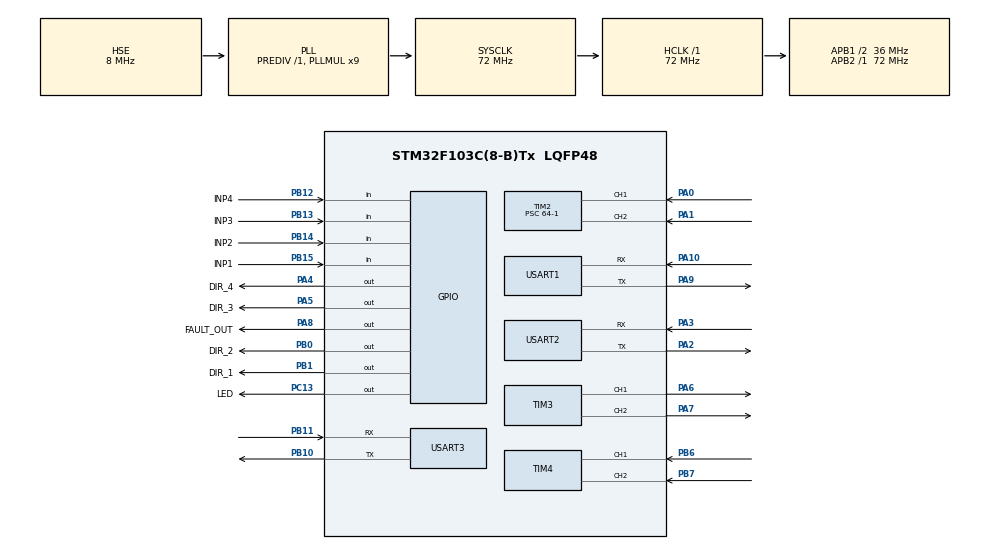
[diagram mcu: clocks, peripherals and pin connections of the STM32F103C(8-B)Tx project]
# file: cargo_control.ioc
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FREERTOS.Mutexes01=modbusMutex,Dynamic,NULL,Available
FREERTOS.Queues01=modbusQueue,10,uint16_t,0,Dynamic,NULL,NULL;uart3RQueue,10,uint16_t,0,Dynamic,NULL,NULL
FREERTOS.Tasks01=MotorTask,24,128,StartMotorTask,Default,NULL,Dynamic,NULL,NULL;modbusTassk,24,128,StartMosbusTask,Default,NULL,Dynamic,NULL,NULL;ledAndRelayTask,24,128,StartLedAndRelayTask,Default,NULL,Dynamic,NULL,NULL;uarrt3RxTask,24,128,StartUart3RxTask,Default,NULL,Dynamic,NULL,NULL
FREERTOS.configTOTAL_HEAP_SIZE=10240
Mcu.Family=STM32F1
Mcu.Name=STM32F103C(8-B)Tx
Mcu.Package=LQFP48
NVIC.PriorityGroup=NVIC_PRIORITYGROUP_4
NVIC.USART1_IRQn=true\:5\:0\:false\:false\:true\:true\:true\:true\:true
NVIC.USART2_IRQn=true\:5\:0\:false\:false\:true\:true\:true\:true\:true
PA0-WKUP.Signal=S_TIM2_CH1_ETR
PA1.Signal=S_TIM2_CH2
PA10.Mode=Asynchronous
PA10.Signal=USART1_RX
PA13.Mode=Serial_Wire
PA13.Signal=SYS_JTMS-SWDIO
PA14.Mode=Serial_Wire
PA14.Signal=SYS_JTCK-SWCLK
PA2.Mode=Asynchronous
PA2.Signal=USART2_TX
PA3.Mode=Asynchronous
PA3.Signal=USART2_RX
PA4.GPIO_Label=DIR_4
PA4.GPIO_Speed=GPIO_SPEED_FREQ_HIGH
PA4.PinState=GPIO_PIN_RESET
PA4.Signal=GPIO_Output
PA5.GPIO_Label=DIR_3
PA5.GPIO_Speed=GPIO_SPEED_FREQ_HIGH
PA5.PinState=GPIO_PIN_RESET
PA5.Signal=GPIO_Output
PA6.Signal=S_TIM3_CH1
PA7.Signal=S_TIM3_CH2
PA8.GPIO_Label=FAULT_OUT
PA8.Signal=GPIO_Output
PA9.Mode=Asynchronous
PA9.Signal=USART1_TX
PB0.GPIO_Label=DIR_2
PB0.GPIO_Speed=GPIO_SPEED_FREQ_HIGH
PB0.PinState=GPIO_PIN_RESET
PB0.Signal=GPIO_Output
PB1.GPIO_Label=DIR_1
PB1.GPIO_Speed=GPIO_SPEED_FREQ_HIGH
PB1.PinState=GPIO_PIN_RESET
PB1.Signal=GPIO_Output
PB10.Mode=Asynchronous
PB10.Signal=USART3_TX
PB11.Mode=Asynchronous
PB11.Signal=USART3_RX
PB12.GPIO_Label=INP4
PB12.GPIO_PuPd=GPIO_PULLUP
PB12.Signal=GPIO_Input
PB13.GPIO_Label=INP3
PB13.GPIO_PuPd=GPIO_PULLUP
PB13.Signal=GPIO_Input
PB14.GPIO_Label=INP2
PB14.GPIO_PuPd=GPIO_PULLUP
PB14.Signal=GPIO_Input
PB15.GPIO_Label=INP1
PB15.GPIO_PuPd=GPIO_PULLUP
PB15.Signal=GPIO_Input
PB6.Signal=S_TIM4_CH1
PB7.Signal=S_TIM4_CH2
PC13-TAMPER-RTC.GPIO_Label=LED
PC13-TAMPER-RTC.Signal=GPIO_Output
PD0-OSC_IN.Mode=HSE-External-Oscillator
PD0-OSC_IN.Signal=RCC_OSC_IN
PD1-OSC_OUT.Mode=HSE-External-Oscillator
PD1-OSC_OUT.Signal=RCC_OSC_OUT
ProjectManager.HeapSize=0x200
ProjectManager.StackSize=0x400
ProjectManager.TargetToolchain=STM32CubeIDE
RCC.AHBFreq_Value=72000000
RCC.APB1CLKDivider=RCC_HCLK_DIV2
RCC.APB1Freq_Value=36000000
RCC.APB1TimFreq_Value=72000000
RCC.APB2Freq_Value=72000000
RCC.APB2TimFreq_Value=72000000
RCC.HCLKFreq_Value=72000000
RCC.PLLMUL=RCC_PLL_MUL9
RCC.PLLSourceVirtual=RCC_PLLSOURCE_HSE
RCC.SYSCLKFreq_VALUE=72000000
RCC.SYSCLKSource=RCC_SYSCLKSOURCE_PLLCLK
RCC.USBFreq_Value=72000000
SH.S_TIM2_CH1_ETR.0=TIM2_CH1,Input_Capture1_from_TI1
SH.S_TIM2_CH2.0=TIM2_CH2,Input_Capture2_from_TI2
SH.S_TIM3_CH1.0=TIM3_CH1,PWM Generation1 CH1
SH.S_TIM3_CH2.0=TIM3_CH2,PWM Generation2 CH2
SH.S_TIM4_CH1.0=TIM4_CH1,Input_Capture1_from_TI1
SH.S_TIM4_CH2.0=TIM4_CH2,Input_Capture2_from_TI2
TIM2.Channel-Input_Capture1_from_TI1=TIM_CHANNEL_1
TIM2.Channel-Input_Capture2_from_TI2=TIM_CHANNEL_2
TIM2.Period=1023
TIM2.Prescaler=64-1
TIM3.Channel-PWM\ Generation1\ CH1=TIM_CHANNEL_1
TIM3.Channel-PWM\ Generation2\ CH2=TIM_CHANNEL_2
TIM4.Channel-Input_Capture1_from_TI1=TIM_CHANNEL_1
TIM4.Channel-Input_Capture2_from_TI2=TIM_CHANNEL_2
USART1.VirtualMode=VM_ASYNC
USART2.VirtualMode=VM_ASYNC
USART3.VirtualMode=VM_ASYNC
VP_FREERTOS_VS_CMSIS_V2.Mode=CMSIS_V2
VP_TIM2_VS_ClockSourceINT.Mode=Internal
VP_TIM4_VS_ClockSourceINT.Mode=Internal
board=custom

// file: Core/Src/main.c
/* USER CODE BEGIN Header */
/**
  ******************************************************************************
  * @file           : main.c
  * @brief          : Main program body
  ******************************************************************************
  * @attention
  *
  * Copyright (c) 2025 STMicroelectronics.
  * All rights reserved.
  *
  * This software is licensed under terms that can be found in the LICENSE file
  * in the root directory of this software component.
  * If no LICENSE file comes with this software, it is provided AS-IS.
  *
  ******************************************************************************
  */
/* USER CODE END Header */
#include "main.h"
#include "cmsis_os.h"
#include "tim.h"
#include "usart.h"
#include "gpio.h"

void SystemClock_Config(void);
void MX_FREERTOS_Init(void);

int main(void)
{

  /* MCU Configuration--------------------------------------------------------*/

  /* Reset of all peripherals, Initializes the Flash interface and the Systick. */
  HAL_Init();

  /* Configure the system clock */
  SystemClock_Config();

  /* Initialize all configured peripherals */
  MX_GPIO_Init();
  MX_USART1_UART_Init();
  MX_USART2_UART_Init();
  MX_USART3_UART_Init();
  MX_TIM2_Init();
  MX_TIM3_Init();
  MX_TIM4_Init();

  /* Init scheduler */
  osKernelInitialize();  /* Call init function for freertos objects (in cmsis_os2.c) */
  MX_FREERTOS_Init();

  /* Start scheduler */
  osKernelStart();

  /* We should never get here as control is now taken by the scheduler */

  /* Infinite loop */
  while (1)
  {

  }
}

void SystemClock_Config(void)
{
  RCC_OscInitTypeDef RCC_OscInitStruct = {0};
  RCC_ClkInitTypeDef RCC_ClkInitStruct = {0};

  /** Initializes the RCC Oscillators according to the specified parameters
  * in the RCC_OscInitTypeDef structure.
  */
  RCC_OscInitStruct.OscillatorType = RCC_OSCILLATORTYPE_HSE;
  RCC_OscInitStruct.HSEState = RCC_HSE_ON;
  RCC_OscInitStruct.HSEPredivValue = RCC_HSE_PREDIV_DIV1;
  RCC_OscInitStruct.HSIState = RCC_HSI_ON;
  RCC_OscInitStruct.PLL.PLLState = RCC_PLL_ON;
  RCC_OscInitStruct.PLL.PLLSource = RCC_PLLSOURCE_HSE;
  RCC_OscInitStruct.PLL.PLLMUL = RCC_PLL_MUL9;
  if (HAL_RCC_OscConfig(&RCC_OscInitStruct) != HAL_OK)
  {
    Error_Handler();
  }

  /** Initializes the CPU, AHB and APB buses clocks
  */
  RCC_ClkInitStruct.ClockType = RCC_CLOCKTYPE_HCLK|RCC_CLOCKTYPE_SYSCLK
                              |RCC_CLOCKTYPE_PCLK1|RCC_CLOCKTYPE_PCLK2;
  RCC_ClkInitStruct.SYSCLKSource = RCC_SYSCLKSOURCE_PLLCLK;
  RCC_ClkInitStruct.AHBCLKDivider = RCC_SYSCLK_DIV1;
  RCC_ClkInitStruct.APB1CLKDivider = RCC_HCLK_DIV2;
  RCC_ClkInitStruct.APB2CLKDivider = RCC_HCLK_DIV1;

  if (HAL_RCC_ClockConfig(&RCC_ClkInitStruct, FLASH_LATENCY_2) != HAL_OK)
  {
    Error_Handler();
  }
}

void Error_Handler(void)
{
  __disable_irq();
  while (1)
  {
  }
}

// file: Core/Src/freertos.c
/* USER CODE BEGIN Header */
/**
  ******************************************************************************
  * File Name          : freertos.c
  * Description        : Code for freertos applications
  ******************************************************************************
  * @attention
  *
  * Copyright (c) 2025 STMicroelectronics.
  * All rights reserved.
  *
  * This software is licensed under terms that can be found in the LICENSE file
  * in the root directory of this software component.
  * If no LICENSE file comes with this software, it is provided AS-IS.
  *
  ******************************************************************************
  */
/* USER CODE END Header */

#include "FreeRTOS.h"
#include "task.h"
#include "main.h"
#include "cmsis_os.h"

/* USER CODE BEGIN Includes */
#include "modbus_rtu.h"
/* USER CODE END Includes */

/* Definitions for MotorTask */
osThreadId_t MotorTaskHandle;
const osThreadAttr_t MotorTask_attributes = {
  .name = "MotorTask",
  .stack_size = 128 * 4,
  .priority = (osPriority_t) osPriorityNormal,
};
/* Definitions for modbusTassk */
osThreadId_t modbusTasskHandle;
const osThreadAttr_t modbusTassk_attributes = {
  .name = "modbusTassk",
  .stack_size = 128 * 4,
  .priority = (osPriority_t) osPriorityNormal,
};
/* Definitions for ledAndRelayTask */
osThreadId_t ledAndRelayTaskHandle;
const osThreadAttr_t ledAndRelayTask_attributes = {
  .name = "ledAndRelayTask",
  .stack_size = 128 * 4,
  .priority = (osPriority_t) osPriorityNormal,
};
/* Definitions for uarrt3RxTask */
osThreadId_t uarrt3RxTaskHandle;
const osThreadAttr_t uarrt3RxTask_attributes = {
  .name = "uarrt3RxTask",
  .stack_size = 128 * 4,
  .priority = (osPriority_t) osPriorityNormal,
};
/* Definitions for modbusQueue */
osMessageQueueId_t modbusQueueHandle;
const osMessageQueueAttr_t modbusQueue_attributes = {
  .name = "modbusQueue"
};
/* Definitions for uart3RQueue */
osMessageQueueId_t uart3RQueueHandle;
const osMessageQueueAttr_t uart3RQueue_attributes = {
  .name = "uart3RQueue"
};
/* Definitions for modbusMutex */
osMutexId_t modbusMutexHandle;
const osMutexAttr_t modbusMutex_attributes = {
  .name = "modbusMutex"
};

void StartMotorTask(void *argument);
void StartMosbusTask(void *argument);
void StartLedAndRelayTask(void *argument);
void StartUart3RxTask(void *argument);

void MX_FREERTOS_Init(void); /* (MISRA C 2004 rule 8.1) */

void MX_FREERTOS_Init(void) {
  /* USER CODE BEGIN Init */
  Modbus_Init();
  /* USER CODE END Init */
  /* Create the mutex(es) */
  /* creation of modbusMutex */
  modbusMutexHandle = osMutexNew(&modbusMutex_attributes);

  /* Create the queue(s) */
  /* creation of modbusQueue */
  modbusQueueHandle = osMessageQueueNew (10, sizeof(uint16_t), &modbusQueue_attributes);

  /* creation of uart3RQueue */
  uart3RQueueHandle = osMessageQueueNew (10, sizeof(uint16_t), &uart3RQueue_attributes);

  /* Create the thread(s) */
  /* creation of MotorTask */
  MotorTaskHandle = osThreadNew(StartMotorTask, NULL, &MotorTask_attributes);

  /* creation of modbusTassk */
  modbusTasskHandle = osThreadNew(StartMosbusTask, NULL, &modbusTassk_attributes);

  /* creation of ledAndRelayTask */
  ledAndRelayTaskHandle = osThreadNew(StartLedAndRelayTask, NULL, &ledAndRelayTask_attributes);

  /* creation of uarrt3RxTask */
  uarrt3RxTaskHandle = osThreadNew(StartUart3RxTask, NULL, &uarrt3RxTask_attributes);

}

void StartMotorTask(void *argument)
{
  for(;;)
  {
    osDelay(1);
  }
}

void StartMosbusTask(void *argument)
{
  /* USER CODE BEGIN StartMosbusTask */
  // Gọi Modbus Task (infinite loop bên trong)
  Modbus_Task(argument);
  /* USER CODE END StartMosbusTask */
}

void StartLedAndRelayTask(void *argument)
{
  /* USER CODE BEGIN StartLedAndRelayTask */
  /* Infinite loop */
  for(;;)
  {
    HAL_GPIO_TogglePin(LED_GPIO_Port, LED_Pin);
    osDelay(200);
  }
  /* USER CODE END StartLedAndRelayTask */
}

void StartUart3RxTask(void *argument)
{
  for(;;)
  {
    osDelay(1);
  }
}
